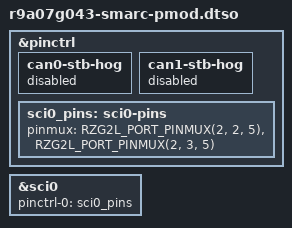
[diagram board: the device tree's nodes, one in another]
// SPDX-License-Identifier: GPL-2.0
/*
 * Device Tree Source for the RZ/{G2UL, Five} SMARC EVK PMOD parts
 *
 * Copyright (C) 2023 Renesas Electronics Corp.
 *
 *
 * [Connection]
 *
 * SMARC EVK
 * +----------------------------+
 * |CN7 (PMOD1 PIN HEADER)      |
 * |	SCI0_TXD	  pin7  |
 * |	SCI0_RXD	  pin8  |
 * |	Gnd		  pin11 |
 * |	Vcc		  pin12 |
 * +----------------------------+
 *
 */

/dts-v1/;
/plugin/;

#include <dt-bindings/pinctrl/rzg2l-pinctrl.h>

&pinctrl {
	can0-stb-hog {
		status = "disabled";
	};

	can1-stb-hog {
		status = "disabled";
	};

	sci0_pins: sci0-pins {
		pinmux = <RZG2L_PORT_PINMUX(2, 2, 5)>, /* TxD */
			 <RZG2L_PORT_PINMUX(2, 3, 5)>; /* RxD */
	};
};

&sci0 {
	pinctrl-0 = <&sci0_pins>;
	pinctrl-names = "default";
	status = "okay";
};
